# CM55F register map
Registers are read-write, no defined reset value unless marked. A register's access mark holds for its fields unless they carry their own. Offsets are from the block's base; lines under a group give offsets from that group; [hi:lo] are bit positions; {n}, {i} and the like mark numbered series; 'fields as' and 'values as' point back to an identical list; <NAME> marks a mode.

## Memory map
0xE0005000 RAS_Ext size 0x9F08 — Reliability, Availability, and Serviceability (RAS) Extension
0xE000E004 ICB size 0xC — Implementation Control Block
0xE000E100 NVIC size 0xF00 — Nested Vectored Interrupt Controller
0xE000ECFC SCB size 0x90 — System Control Block
0xE000EF34 FP_MVE size 0x18 — Floating-point and MVE Extension
0xE001E000 MSC size 0x19D00 — Memory System Control Registers
0xE001E100 ERRBNK size 0x8 — Implementation defined error banking
0xE001E200 DCA size 0x10 — Direct Cache Access

## NVIC — Nested Vectored Interrupt Controller
Base 0xE000E100
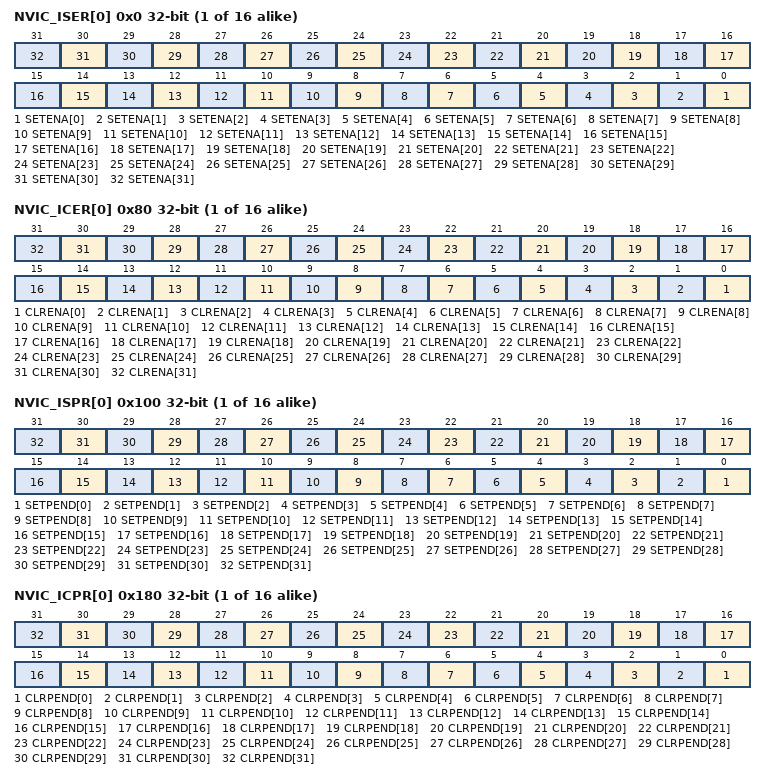
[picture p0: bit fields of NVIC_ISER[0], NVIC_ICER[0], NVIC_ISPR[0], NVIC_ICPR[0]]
{0x0+4i} NVIC_ISER[{i}] (i=0..15) — Interrupt Set Enable Register enables or reads the enabled state of each group of 32 interrupts
  [n] SETENA[{n}] (n=0..31) — Interrupt set-enable bits. For SETENA[m] in NVIC_ISERn, allows interrupt 32n+m to be accessed.
    0=On reads, interrupt disabled; 1=On reads, interrupt enabled
{0x80+4i} NVIC_ICER[{i}] (i=0..15) — Interrupt Clear Enable Register disables or reads the enable state of a group of interrupts
  [n] CLRENA[{n}] (n=0..31) — Interrupt clear-enable bits. For SETENA[m] in NVIC_ICERn, allows interrupt 32n+m to be accessed.
    values as NVIC_ISER[0].SETENA[0]
{0x100+4i} NVIC_ISPR[{i}] (i=0..15) — Interrupt Set Pending Register changes status to pending, or shows the current pending status for a group of interrupts
  [n] SETPEND[{n}] (n=0..31) — Interrupt set-pending bits. For SETPEND[m] in NVIC_ISPRn, allows interrupt 32n + m to be accessed.
    0=On reads, interrupt is not pending; 1=On reads, interrupt is pending
{0x180+4i} NVIC_ICPR[{i}] (i=0..15) — Interrupt Clear Pending Register clears the pending status, or shows the current pending status for a group of interrupts
  [n] CLRPEND[{n}] (n=0..31) — Interrupt clear-pending bits. Clears the pending state of interrupt (m+(32*n)), or shows whether the state of the interrupt is pending
    0=On reads, interrupt is not pending; 1=On reads, interrupt is pending; on writes, clear pending state
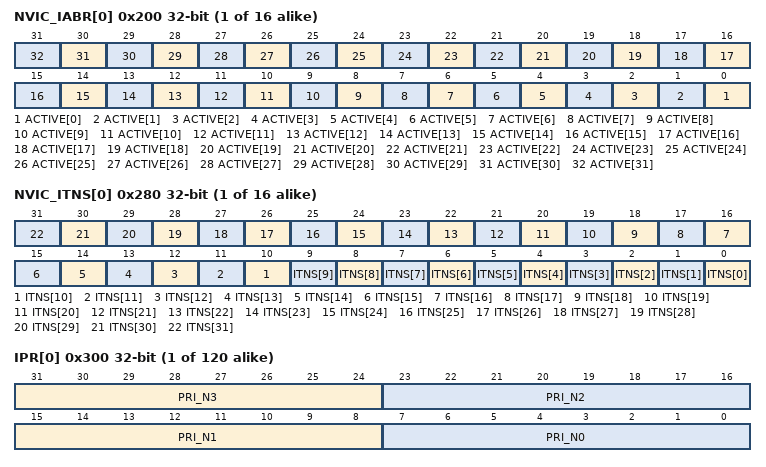
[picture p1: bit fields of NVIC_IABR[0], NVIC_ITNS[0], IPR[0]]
{0x200+4i} NVIC_IABR[{i}] (i=0..15) ro — Interrupt Active Bit Register shows whether each interrupt is active for a group of 32 interrupts
  [n] ACTIVE[{n}] (n=0..31) — For ACTIVE[m] in NVIC_IABRn, indicates the active state for interrupt 32n+m.
    0=Interrupt not active; 1=Interrupt active
{0x280+4i} NVIC_ITNS[{i}] (i=0..15) — Interrupt Targete Non-Secure Register specifies or reads whether each interrupt targets non-secure or secure state for a group of interrupts
  [n] ITNS[{n}] (n=0..31) — For ITNS[m] in NVIC_ITNSn, this field indicates and allows modification of the target Security state for interrupt 32n+m.
    0=Interrupt targets secure state; 1=Interrupt targets non-secure state
{0x300+4i} IPR[{i}] (i=0..119) — Interrupt Priority Register sets or reads interrupt priorities
  [31:24] PRI_N3 — For register NVIC_IPRn, priority of interrupt number 4n+3
  [23:16] PRI_N2 — For register NVIC_IPRn, priority of interrupt number 4n+2
  [15:8] PRI_N1 — For register NVIC_IPRn, priority of interrupt number 4n+1
  [7:0] PRI_N0 — For register NVIC_IPRn, priority of interrupt number 4n
0xE00 STIR wo — Software Trigger Interrupt Register write to the STIR to generate an interrupt from software.
  [8:0] INTID — Interrupt ID of the interrupt to trigger, in the range 0-479.

## MSC — Memory System Control Registers
Base 0xE001E000
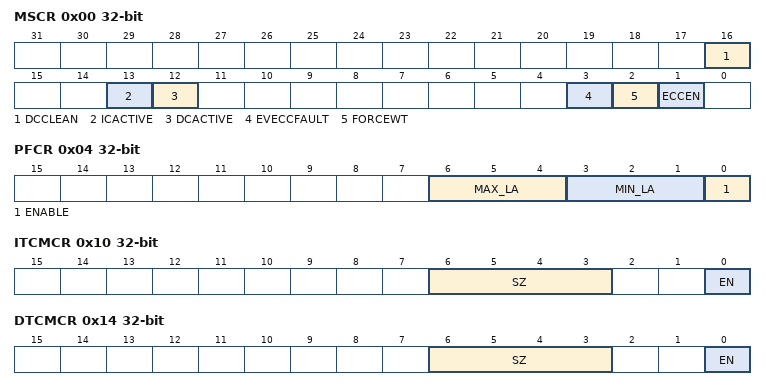
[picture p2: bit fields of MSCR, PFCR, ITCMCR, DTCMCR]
0x00 MSCR — Memory System Control Register controls the memory system features specific to the processor
  [16] DCCLEAN — Indicates whether the data cache contains any dirty lines
    0=Level 1 (L1) data cache contains at least one dirty line; 1=L1 data cache does not contain any dirty lines
  [13] ICACTIVE — Indicates whether the L1 instruction cache is active
    0=L1 instruction cache is inactive; 1=L1 instruction cache is active
  [12] DCACTIVE — Indicates whether the L1 data cache is active
    0=L1 data cache is inactive; 1=L1 data cache is active
  [3] EVECCFAULT — Enables asynchronous BusFault exceptions when data is lost on evictions
    0=Asynchronous BusFaults are not generated when evicting lines with multi-bit errors in the data; 1=Asynchronous aborts are generated when evicting lines with multi-errors in the data
  [2] FORCEWT — Enables Forced Write-Through in the L1 data cache
    0=Force Write-Through is disabled; 1=Force Write-Through is enabled
  [1] ECCEN — Indicates whether Error Correcting Code (ECC) is present and enabled
    0=ECC not present or not enabled; 1=ECC present and enabled
0x04 PFCR — Prefetcher Control Register controls the prefetcher
  [6:4] MAX_LA — This bit field is not used, and is RES0
  [3:1] MIN_LA — This bit field is not used, and is RES0
  [0] ENABLE — Prefetcher enable
    0=Prefetcher is disabled; 1=Prefetcher is enabled
0x10 ITCMCR — ITCM Control Register enable access to the Tightly Coupled Memories (TCMs) by software running on the processor
  [6:3] SZ — Indicates the size of the relevant TCM
    0=No TCM implemented; 3=4KB; 4=8KB; 5=16KB; 6=32KB; 7=64KB; 8=128KB; 9=256KB; 10=512KB; 11=1MB; 12=2MB; 13=4MB; 14=8MB; 15=16MB
  [0] EN — TCM enable
    0=TCM disabled; 1=TCM enabled
0x14 DTCMCR — DTCM Control Register enable access to the Tightly Coupled Memories (TCMs) by software running on the processor
  fields as ITCMCR
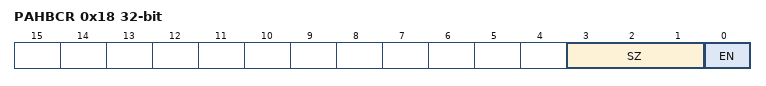
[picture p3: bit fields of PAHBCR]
0x18 PAHBCR — P-AHB Control Register enables accesses to Peripheral AHB (P-AHB) interface from software running on the processor
  [3:1] SZ — P-AHB size
    0=0MB. This implies that P-AHB disabled.; 1=64MB; 2=128MB; 3=256MB; 4=512MB
  [0] EN — P-AHB enable
    0=P-AHB disabled; 1=P-AHB enabled
